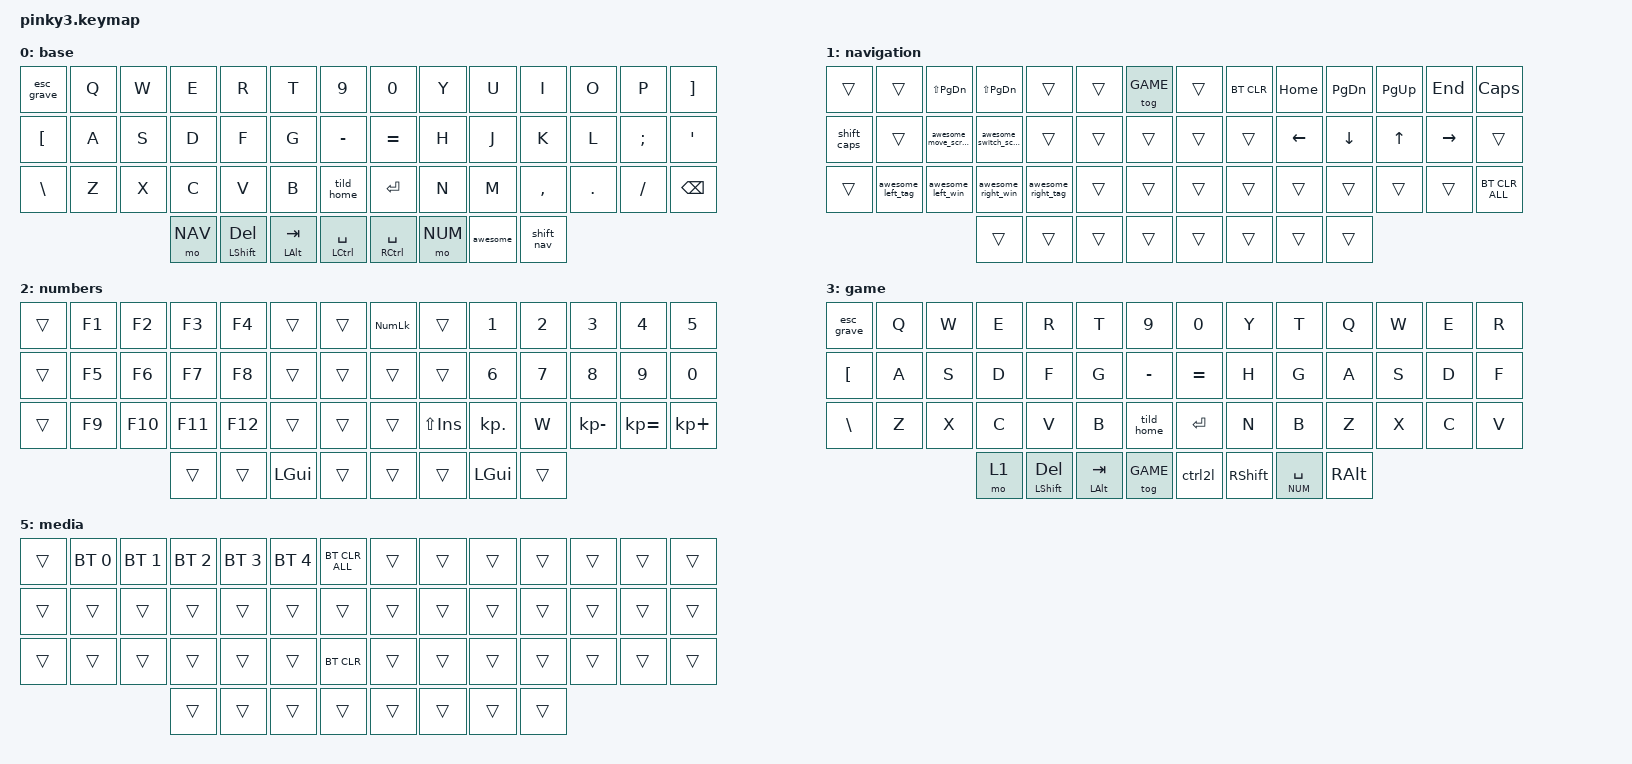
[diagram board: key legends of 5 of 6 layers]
#include <behaviors.dtsi>
#include <dt-bindings/zmk/bt.h>
#include <dt-bindings/zmk/keys.h>

#define BASE 0
#define NAV 1
#define NUM 2
#define GAME 3
#define RASL 4
#define TAP_SPEED 100

&mt { tapping-term-ms = <200>; };

/ {
    combos {
        compatible = "zmk,combos";

        combo_parenl {
            timeout-ms = <50>;
            key-positions = <23 24>;
            bindings = <&kp LS(N9)>;
        };

        combo_parenr {
            timeout-ms = <50>;
            key-positions = <25 26>;
            bindings = <&kp LS(N0)>;
        };

        mediaLayer {
            bindings = <&mo 5>;
            key-positions = <42 43>;
        };
    };

    macros {
        awesome_left_tag: awesome_left_tag {
            compatible = "zmk,behavior-macro";
            label = "AWESOME_LEFT_TAG";
            #binding-cells = <0>;
            bindings =
                <&macro_press>,
                <&kp LEFT_GUI>,
                <&macro_tap>,
                <&kp LEFT_ARROW>,
                <&macro_release>,
                <&kp LEFT_GUI>;
        };

        awesome_left_win: awesome_left_win {
            compatible = "zmk,behavior-macro";
            label = "AWESOME_LEFT_WIN";
            #binding-cells = <0>;
            bindings =
                <&macro_press>,
                <&kp LEFT_GUI>,
                <&macro_tap>,
                <&kp V>,
                <&macro_release>,
                <&kp LEFT_GUI>;
        };

        awesome_right_win: awesome_right_win {
            compatible = "zmk,behavior-macro";
            label = "AWESOME_RIGHT_WIN";
            #binding-cells = <0>;
            bindings =
                <&macro_press>,
                <&kp LEFT_GUI>,
                <&macro_tap>,
                <&kp C>,
                <&macro_release>,
                <&kp LEFT_GUI>;
        };

        awesome_right_tag: awesome_right_tag {
            compatible = "zmk,behavior-macro";
            label = "AWESOME_RIGHT_TAG";
            #binding-cells = <0>;
            bindings =
                <&macro_press>,
                <&kp LEFT_GUI>,
                <&macro_tap>,
                <&kp RIGHT>,
                <&macro_release>,
                <&kp LEFT_GUI>;
        };

        awesome_move_screen: awesome_move_screen {
            compatible = "zmk,behavior-macro";
            label = "AWESOME_MOVE_SCREEN";
            #binding-cells = <0>;
            bindings =
                <&macro_press>,
                <&kp LEFT_GUI>,
                <&macro_tap>,
                <&kp S>,
                <&macro_release>,
                <&kp LEFT_GUI>;
        };

        awesome_switch_screen: awesome_switch_screen {
            compatible = "zmk,behavior-macro";
            label = "awesome_switch_screen";
            #binding-cells = <0>;
            bindings =
                <&macro_press>,
                <&kp LEFT_GUI &kp LCTRL>,
                <&macro_tap>,
                <&kp V>,
                <&macro_release>,
                <&kp LCTRL &kp LEFT_GUI>;
        };

        triple_grave: triple_grave {
            compatible = "zmk,behavior-macro";
            label = "TRIPLE_GRAVE";
            #binding-cells = <0>;
            bindings = <&kp GRAVE &kp GRAVE &kp GRAVE>;
        };

        homepath: homepath {
            compatible = "zmk,behavior-macro";
            label = "HOMEPATH";
            #binding-cells = <0>;
            bindings = <&kp TILDE &kp LEFT_BRACKET>;
        };

        awesome_num: awesome_num {
            compatible = "zmk,behavior-macro";
            label = "awesome_win_tag";
            #binding-cells = <0>;
            wait-ms = <0>;
            bindings =
                <&macro_press>,
                <&mo NUM &kp LGUI>,
                <&macro_pause_for_release>,
                <&macro_release>,
                <&mo NUM &kp LGUI>;
        };

        shift_caps: shift_caps {
            compatible = "zmk,behavior-macro";
            label = "shift+casp";
            #binding-cells = <0>;
            bindings =
                <&macro_press>,
                <&kp LSHIFT &kp CAPSLOCK>,
                <&macro_release>,
                <&kp LSHIFT &kp CAPSLOCK>;
        };
    };

    behaviors {
        tild_home: tild_home {
            compatible = "zmk,behavior-tap-dance";
            label = "TILD_HOME";
            #binding-cells = <0>;
            bindings = <&kp TILDE>, <&homepath>, <&triple_grave>;
        };

        esc_grave: esc_grave {
            compatible = "zmk,behavior-mod-morph";
            label = "ESC_GRAVE";
            mods = <(MOD_LSFT|MOD_RSFT)>;
            #binding-cells = <0>;
            bindings = <&kp ESC>, <&kp GRAVE>;
        };

        awesome: awesome {
            compatible = "zmk,behavior-tap-dance";
            label = "AWESOME";
            #binding-cells = <0>;
            tapping-term-ms = <200>;
            bindings = <&kp RGUI>, <&awesome_num>;
        };

        ctrl2l: ctrl2l {
            compatible = "zmk,behavior-tap-dance";
            label = "CTRL2LEFT";
            #binding-cells = <0>;
            tapping-term-ms = <200>;
            bindings = <&kp LCTRL>, <&mo RASL>;
        };

        shift_nav: shift_nav {
            compatible = "zmk,behavior-tap-dance";
            label = "SHIFT_OR_NAV";
            #binding-cells = <0>;
            tapping-term-ms = <100>;
            bindings = <&kp RSHIFT>, <&mo NAV>;
        };
    };

    keymap {
        compatible = "zmk,keymap";

        base {
            bindings = <
&esc_grave        &kp Q  &kp W  &kp E    &kp R           &kp T         &kp N9           &kp N0           &kp Y    &kp U     &kp I       &kp O    &kp P     &kp RIGHT_BRACKET
&kp LEFT_BRACKET  &kp A  &kp S  &kp D    &kp F           &kp G         &kp MINUS        &kp EQUAL        &kp H    &kp J     &kp K       &kp L    &kp SEMI  &kp QUOT
&kp BSLH          &kp Z  &kp X  &kp C    &kp V           &kp B         &tild_home       &kp ENTER        &kp N    &kp M     &kp COMMA   &kp DOT  &kp FSLH  &kp BSPC
                                &mo NAV  &mt LSHIFT DEL  &mt LALT TAB  &mt LCTRL SPACE  &mt RCTRL SPACE  &mo NUM  &awesome  &shift_nav
            >;

            label = "base";
        };

        nav {
            bindings = <
&trans       &trans             &kp LS(PAGE_DOWN)     &kp LS(PAGE_DOWN)       &trans              &trans  &tog GAME  &trans  &bt BT_CLR  &kp HOME  &kp PG_DN  &kp PG_UP  &kp END    &kp CAPSLOCK
&shift_caps  &trans             &awesome_move_screen  &awesome_switch_screen  &trans              &trans  &trans     &trans  &trans      &kp LEFT  &kp DOWN   &kp UP     &kp RIGHT  &trans
&trans       &awesome_left_tag  &awesome_left_win     &awesome_right_win      &awesome_right_tag  &trans  &trans     &trans  &trans      &trans    &trans     &trans     &trans     &bt BT_CLR_ALL
                                                      &trans                  &trans              &trans  &trans     &trans  &trans      &trans    &trans
            >;

            label = "navigation";
        };

        num {
            bindings = <
&trans  &kp F1  &kp F2   &kp F3   &kp F4   &trans    &trans  &kp KP_NUM  &trans       &kp N1      &kp N2  &kp N3        &kp N4        &kp N5
&trans  &kp F5  &kp F6   &kp F7   &kp F8   &trans    &trans  &trans      &trans       &kp N6      &kp N7  &kp N8        &kp N9        &kp N0
&trans  &kp F9  &kp F10  &kp F11  &kp F12  &trans    &trans  &trans      &kp LS(INS)  &kp KP_DOT  &kp W   &kp KP_MINUS  &kp KP_EQUAL  &kp KP_PLUS
                         &trans   &trans   &kp LGUI  &trans  &trans      &trans       &kp LGUI    &trans
            >;

            label = "numbers";
        };

        game {
            bindings = <
&esc_grave        &kp Q  &kp W  &kp E  &kp R           &kp T         &kp N9      &kp N0     &kp Y       &kp T          &kp Q     &kp W  &kp E  &kp R
&kp LEFT_BRACKET  &kp A  &kp S  &kp D  &kp F           &kp G         &kp MINUS   &kp EQUAL  &kp H       &kp G          &kp A     &kp S  &kp D  &kp F
&kp BSLH          &kp Z  &kp X  &kp C  &kp V           &kp B         &tild_home  &kp ENTER  &kp N       &kp B          &kp Z     &kp X  &kp C  &kp V
                                &mo 1  &mt LSHIFT DEL  &mt LALT TAB  &tog GAME   &ctrl2l    &kp RSHIFT  &mt NUM SPACE  &kp RALT
            >;

            label = "game";
        };

        rasl {
            bindings = <
&esc_grave  &kp Q  &kp W  &kp E      &kp R       &kp T      &kp N9     &kp N0     &kp U    &kp I     &kp O     &kp P     &kp RIGHT_BRACKET  &kp LEFT_BRACKET
&kp A       &kp S  &kp D  &kp F      &kp G       &kp MINUS  &kp EQUAL  &kp J      &kp K    &kp L     &kp SEMI  &kp QUOT  &kp BSLH           &kp Z
&kp X       &kp C  &kp V  &kp B      &tild_home  &kp ENTER  &kp M      &kp COMMA  &kp DOT  &kp FSLH  &kp BSPC  &mo 1     &mt LSHIFT DEL     &mt LALT TAB
                          &tog GAME  &trans      &trans     &trans     &trans
            >;

            label = "rasl";
        };

        media {
            bindings = <
&trans  &bt BT_SEL 0  &bt BT_SEL 1  &bt BT_SEL 2  &bt BT_SEL 3  &bt BT_SEL 4  &bt BT_CLR_ALL  &trans  &trans  &trans  &trans  &trans  &trans  &trans
&trans  &trans        &trans        &trans        &trans        &trans        &trans          &trans  &trans  &trans  &trans  &trans  &trans  &trans
&trans  &trans        &trans        &trans        &trans        &trans        &bt BT_CLR      &trans  &trans  &trans  &trans  &trans  &trans  &trans
                                    &trans        &trans        &trans        &trans          &trans  &trans  &trans  &trans
            >;
        };
    };
};
